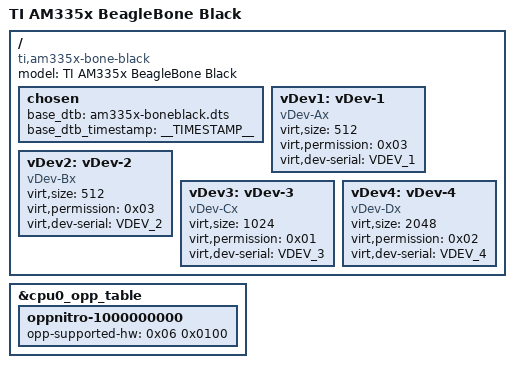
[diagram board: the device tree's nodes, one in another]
// SPDX-License-Identifier: GPL-2.0-only
/*
 * Copyright (C) 2012 Texas Instruments Incorporated - http://www.ti.com/
 */
/dts-v1/;

#include "am33xx.dtsi"
#include "am335x-bone-common.dtsi"
#include "am335x-boneblack-common.dtsi"

/ {
	model = "TI AM335x BeagleBone Black";
	compatible = "ti,am335x-bone-black", "ti,am335x-bone", "ti,am33xx";

	chosen {
		base_dtb = "am335x-boneblack.dts";
		base_dtb_timestamp = __TIMESTAMP__;
	};
};

&cpu0_opp_table {
	/*
	 * All PG 2.0 silicon may not support 1GHz but some of the early
	 * BeagleBone Blacks have PG 2.0 silicon which is guaranteed
	 * to support 1GHz OPP so enable it for PG 2.0 on this board.
	 */
	oppnitro-1000000000 {
		opp-supported-hw = <0x06 0x0100>;
	};
};

/ {
  
    vDev1: vDev-1 {
        compatible = "vDev-Ax";
        virt,size = <512>;
        virt,permission = <0x03>;
        virt,dev-serial = "VDEV_1";
    };

    vDev2: vDev-2 {
        compatible = "vDev-Bx";
        virt,size = <512>;
        virt,permission = <0x03>;
        virt,dev-serial = "VDEV_2";
    };

    vDev3: vDev-3 {
        compatible = "vDev-Cx";
        virt,size = <1024>;
        virt,permission = <0x01>;
        virt,dev-serial = "VDEV_3";
    };

    vDev4: vDev-4 {
        compatible = "vDev-Dx";
        virt,size = <2048>;
        virt,permission = <0x02>;
        virt,dev-serial = "VDEV_4";
    };
};
